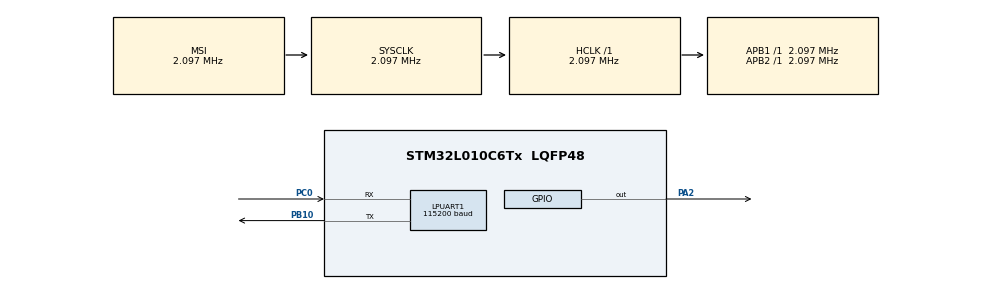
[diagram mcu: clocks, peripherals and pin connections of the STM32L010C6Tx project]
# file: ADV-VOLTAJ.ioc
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LPUART1.BaudRate=115200
LPUART1.WordLength=UART_WORDLENGTH_8B
Mcu.Family=STM32L0
Mcu.Name=STM32L010C6Tx
Mcu.Package=LQFP48
PA13.Mode=Serial_Wire
PA13.Signal=SYS_SWDIO
PA14.Mode=Serial_Wire
PA14.Signal=SYS_SWCLK
PA2.Signal=GPIO_Output
PB10.Mode=Asynchronous
PB10.Signal=LPUART1_TX
PC0.Mode=Asynchronous
PC0.Signal=LPUART1_RX
PH0-OSC_IN.Mode=HSE-External-Oscillator
PH0-OSC_IN.Signal=RCC_OSC_IN
PH1-OSC_OUT.Mode=HSE-External-Oscillator
PH1-OSC_OUT.Signal=RCC_OSC_OUT
ProjectManager.HeapSize=0x200
ProjectManager.StackSize=0x400
ProjectManager.TargetToolchain=STM32CubeIDE
RCC.AHBFreq_Value=2097000
RCC.APB1Freq_Value=2097000
RCC.APB1TimFreq_Value=2097000
RCC.APB2Freq_Value=2097000
RCC.APB2TimFreq_Value=2097000
RCC.HSE_VALUE=8000000
RCC.HSI16_VALUE=16000000
RCC.HSI_VALUE=16000000
RCC.LSE_VALUE=32768
RCC.MSI_VALUE=2097000
RCC.SYSCLKFreq_VALUE=2097000
RCC.VCOOutputFreq_Value=48000000
VP_ADC_Vref_Input.Mode=IN-Vrefint
board=custom

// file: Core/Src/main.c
/* USER CODE BEGIN Header */
/**
  ******************************************************************************
  * @file           : main.c
  * @brief          : Main program body
  ******************************************************************************
  * @attention
  *
  * <h2><center>&copy; Copyright (c) 2022 STMicroelectronics.
  * All rights reserved.</center></h2>
  *
  * This software component is licensed by ST under BSD 3-Clause license,
  * the "License"; You may not use this file except in compliance with the
  * License. You may obtain a copy of the License at:
  *                        opensource.org/licenses/BSD-3-Clause
  *
  ******************************************************************************
  */
/* USER CODE END Header */
#include "main.h"

/* USER CODE BEGIN PD */
#define VREFINT_CAL_ADDR			0x1FF80078
#define VREFINT_CAL 				((uint16_t*) VREFINT_CAL_ADDR)

char buffer[23];
/* USER CODE END PD */

ADC_HandleTypeDef hadc;

UART_HandleTypeDef hlpuart1;

void SystemClock_Config(void);
static void MX_GPIO_Init(void);
static void MX_ADC_Init(void);
static void MX_LPUART1_UART_Init(void);

int main(void)
{

  /* MCU Configuration--------------------------------------------------------*/

  /* Reset of all peripherals, Initializes the Flash interface and the Systick. */
  HAL_Init();

  /* Configure the system clock */
  SystemClock_Config();

  /* Initialize all configured peripherals */
  MX_GPIO_Init();
  MX_ADC_Init();
  MX_LPUART1_UART_Init();
  /* USER CODE BEGIN 2 */
  HAL_ADCEx_Calibration_Start(&hadc, ADC_SINGLE_ENDED);
  /* USER CODE END 2 */

  /* Infinite loop */
  while (1)
  {

    /* USER CODE BEGIN 3 */
	  HAL_ADC_Start(&hadc);

	  	HAL_ADC_PollForConversion(&hadc, 100);
	  	uint16_t VREFINTADC = HAL_ADC_GetValue(&hadc);
	  	HAL_ADC_Stop(&hadc);
	  	float VDD = 3000.0 * (*VREFINT_CAL / (float) VREFINTADC);

  }
  /* USER CODE END 3 */
}

void SystemClock_Config(void)
{
  RCC_OscInitTypeDef RCC_OscInitStruct = {0};
  RCC_ClkInitTypeDef RCC_ClkInitStruct = {0};
  RCC_PeriphCLKInitTypeDef PeriphClkInit = {0};

  /** Configure the main internal regulator output voltage
  */
  __HAL_PWR_VOLTAGESCALING_CONFIG(PWR_REGULATOR_VOLTAGE_SCALE1);
  /** Initializes the RCC Oscillators according to the specified parameters
  * in the RCC_OscInitTypeDef structure.
  */
  RCC_OscInitStruct.OscillatorType = RCC_OSCILLATORTYPE_MSI;
  RCC_OscInitStruct.MSIState = RCC_MSI_ON;
  RCC_OscInitStruct.MSICalibrationValue = 0;
  RCC_OscInitStruct.MSIClockRange = RCC_MSIRANGE_5;
  RCC_OscInitStruct.PLL.PLLState = RCC_PLL_NONE;
  if (HAL_RCC_OscConfig(&RCC_OscInitStruct) != HAL_OK)
  {
    Error_Handler();
  }
  /** Initializes the CPU, AHB and APB buses clocks
  */
  RCC_ClkInitStruct.ClockType = RCC_CLOCKTYPE_HCLK|RCC_CLOCKTYPE_SYSCLK
                              |RCC_CLOCKTYPE_PCLK1|RCC_CLOCKTYPE_PCLK2;
  RCC_ClkInitStruct.SYSCLKSource = RCC_SYSCLKSOURCE_MSI;
  RCC_ClkInitStruct.AHBCLKDivider = RCC_SYSCLK_DIV1;
  RCC_ClkInitStruct.APB1CLKDivider = RCC_HCLK_DIV1;
  RCC_ClkInitStruct.APB2CLKDivider = RCC_HCLK_DIV1;

  if (HAL_RCC_ClockConfig(&RCC_ClkInitStruct, FLASH_LATENCY_0) != HAL_OK)
  {
    Error_Handler();
  }
  PeriphClkInit.PeriphClockSelection = RCC_PERIPHCLK_LPUART1;
  PeriphClkInit.Lpuart1ClockSelection = RCC_LPUART1CLKSOURCE_PCLK1;
  if (HAL_RCCEx_PeriphCLKConfig(&PeriphClkInit) != HAL_OK)
  {
    Error_Handler();
  }
}

static void MX_ADC_Init(void)
{

  ADC_ChannelConfTypeDef sConfig = {0};

  /** Configure the global features of the ADC (Clock, Resolution, Data Alignment and number of conversion)
  */
  hadc.Instance = ADC1;
  hadc.Init.OversamplingMode = DISABLE;
  hadc.Init.ClockPrescaler = ADC_CLOCK_SYNC_PCLK_DIV1;
  hadc.Init.Resolution = ADC_RESOLUTION_12B;
  hadc.Init.SamplingTime = ADC_SAMPLETIME_1CYCLE_5;
  hadc.Init.ScanConvMode = ADC_SCAN_DIRECTION_FORWARD;
  hadc.Init.DataAlign = ADC_DATAALIGN_RIGHT;
  hadc.Init.ContinuousConvMode = DISABLE;
  hadc.Init.DiscontinuousConvMode = DISABLE;
  hadc.Init.ExternalTrigConvEdge = ADC_EXTERNALTRIGCONVEDGE_NONE;
  hadc.Init.ExternalTrigConv = ADC_SOFTWARE_START;
  hadc.Init.DMAContinuousRequests = DISABLE;
  hadc.Init.EOCSelection = ADC_EOC_SINGLE_CONV;
  hadc.Init.Overrun = ADC_OVR_DATA_PRESERVED;
  hadc.Init.LowPowerAutoWait = DISABLE;
  hadc.Init.LowPowerFrequencyMode = ENABLE;
  hadc.Init.LowPowerAutoPowerOff = DISABLE;
  if (HAL_ADC_Init(&hadc) != HAL_OK)
  {
    Error_Handler();
  }
  /** Configure for the selected ADC regular channel to be converted.
  */
  sConfig.Channel = ADC_CHANNEL_VREFINT;
  sConfig.Rank = ADC_RANK_CHANNEL_NUMBER;
  if (HAL_ADC_ConfigChannel(&hadc, &sConfig) != HAL_OK)
  {
    Error_Handler();
  }

}

static void MX_LPUART1_UART_Init(void)
{

  hlpuart1.Instance = LPUART1;
  hlpuart1.Init.BaudRate = 115200;
  hlpuart1.Init.WordLength = UART_WORDLENGTH_8B;
  hlpuart1.Init.StopBits = UART_STOPBITS_1;
  hlpuart1.Init.Parity = UART_PARITY_NONE;
  hlpuart1.Init.Mode = UART_MODE_TX_RX;
  hlpuart1.Init.HwFlowCtl = UART_HWCONTROL_NONE;
  hlpuart1.Init.OneBitSampling = UART_ONE_BIT_SAMPLE_DISABLE;
  hlpuart1.AdvancedInit.AdvFeatureInit = UART_ADVFEATURE_NO_INIT;
  if (HAL_UART_Init(&hlpuart1) != HAL_OK)
  {
    Error_Handler();
  }

}

static void MX_GPIO_Init(void)
{
  GPIO_InitTypeDef GPIO_InitStruct = {0};

  /* GPIO Ports Clock Enable */
  __HAL_RCC_GPIOC_CLK_ENABLE();
  __HAL_RCC_GPIOH_CLK_ENABLE();
  __HAL_RCC_GPIOA_CLK_ENABLE();
  __HAL_RCC_GPIOB_CLK_ENABLE();

  /*Configure GPIO pin Output Level */
  HAL_GPIO_WritePin(GPIOA, GPIO_PIN_2, GPIO_PIN_RESET);

  /*Configure GPIO pin : PA2 */
  GPIO_InitStruct.Pin = GPIO_PIN_2;
  GPIO_InitStruct.Mode = GPIO_MODE_OUTPUT_PP;
  GPIO_InitStruct.Pull = GPIO_NOPULL;
  GPIO_InitStruct.Speed = GPIO_SPEED_FREQ_LOW;
  HAL_GPIO_Init(GPIOA, &GPIO_InitStruct);

  /*Configure GPIO pin : PB0 */
  GPIO_InitStruct.Pin = GPIO_PIN_0;
  GPIO_InitStruct.Mode = GPIO_MODE_ANALOG;
  GPIO_InitStruct.Pull = GPIO_NOPULL;
  HAL_GPIO_Init(GPIOB, &GPIO_InitStruct);

}

void Error_Handler(void)
{
  __disable_irq();
  while (1)
  {
  }
}

/************************ (C) COPYRIGHT STMicroelectronics *****END OF FILE****/
